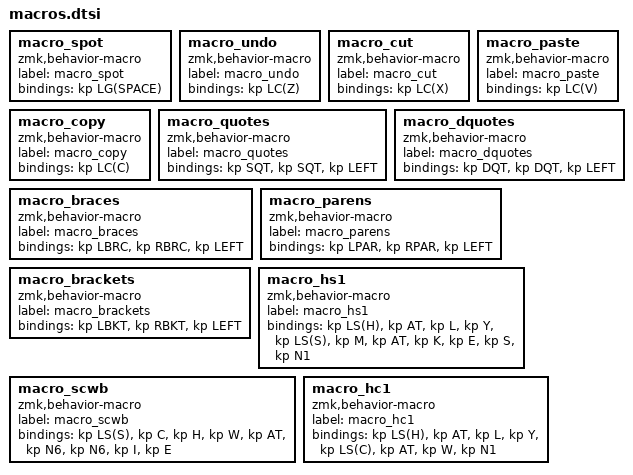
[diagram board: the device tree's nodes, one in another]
macro_spot: macro_spot{
compatible = "zmk,behavior-macro";
label = "macro_spot";
#binding-cells = <0>;
bindings = <&kp LG(SPACE)>;
};
macro_undo: macro_undo{
compatible = "zmk,behavior-macro";
label = "macro_undo";
#binding-cells = <0>;
bindings = <&kp LC(Z)>;
};
macro_cut: macro_cut{
compatible = "zmk,behavior-macro";
label = "macro_cut";
#binding-cells = <0>;
bindings = <&kp LC(X)>;
};
macro_paste: macro_paste{
compatible = "zmk,behavior-macro";
label = "macro_paste";
#binding-cells = <0>;
bindings = <&kp LC(V)>;
};
macro_copy: macro_copy{
compatible = "zmk,behavior-macro";
label = "macro_copy";
#binding-cells = <0>;
bindings = <&kp LC(C)>;
};
macro_quotes: macro_quotes{
compatible = "zmk,behavior-macro";
label = "macro_quotes";
#binding-cells = <0>;
bindings = <&kp SQT>, <&kp SQT>, <&kp LEFT>;
};
macro_dquotes: macro_dquotes{
compatible = "zmk,behavior-macro";
label = "macro_dquotes";
#binding-cells = <0>;
bindings = <&kp DQT>, <&kp DQT>, <&kp LEFT>;
};
macro_braces: macro_braces{
compatible = "zmk,behavior-macro";
label = "macro_braces";
#binding-cells = <0>;
bindings = <&kp LBRC>, <&kp RBRC>, <&kp LEFT>;
};
macro_parens: macro_parens{
compatible = "zmk,behavior-macro";
label = "macro_parens";
#binding-cells = <0>;
bindings = <&kp LPAR>, <&kp RPAR>, <&kp LEFT>;
};
macro_brackets: macro_brackets{
compatible = "zmk,behavior-macro";
label = "macro_brackets";
#binding-cells = <0>;
bindings = <&kp LBKT>, <&kp RBKT>, <&kp LEFT>;
};
macro_hs1: macro_hs1{
compatible = "zmk,behavior-macro";
label = "macro_hs1";
#binding-cells = <0>;
bindings = <&kp LS(H)>, <&kp AT>, <&kp L>, <&kp Y>, <&kp LS(S)>, <&kp M>, <&kp AT>, <&kp K>, <&kp E>, <&kp S>, <&kp N1>;
};
macro_scwb: macro_scwb{
compatible = "zmk,behavior-macro";
label = "macro_scwb";
#binding-cells = <0>;
bindings = <&kp LS(S)>, <&kp C>, <&kp H>, <&kp W>, <&kp AT>, <&kp N6>, <&kp N6>, <&kp I>, <&kp E>;
};
macro_hc1: macro_hc1{
compatible = "zmk,behavior-macro";
label = "macro_hc1";
#binding-cells = <0>;
bindings = <&kp LS(H)>, <&kp AT>, <&kp L>, <&kp Y>, <&kp LS(C)>, <&kp AT>, <&kp W>, <&kp N1>;
};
